# M2Sxxx register map
Vendor: Microsemi; Series: SmartFusion2; File version: 2.0.32
CPU: CM3 r2p1, little endian, MPU, no FPU, 4 interrupt priority bits
Registers are 32-bit, read-write, no defined reset value unless marked. A register's access mark holds for its fields unless they carry their own. Offsets are from the block's base; [hi:lo] are bit positions; {n}, {i} and the like mark numbered series.

## MMUART_0 — Multi-mode universal asynchronous/synchronous receiver/transmitter peripheral
Base 0x40000000
Same registers: MMUART_1 0x40010000
0x00 RBR 8-bit — Receiver buffer register. This register holds the receive data bits for MMUART_x. The default value is unknown since the register is loaded with data in the receive FIFO. Bit 0 is the LSB and it is the first bit received. It may be configured as the MSB by configuring the E_MSB_RX bit in the MM1. The divisor latch access bit (DLAB), bit 7 of LCR, must be 0 to read this register. This register is read only. Writing to this register with the DLAB 0 changes the transmit holding register (THR) register value.
0x00 THR 8-bit (alternate view of RBR) — Transmit holding register. This register holds the data bits to be transmitted. Bit 0 is the LSB and is transmitted first. The MSB may be transmitted first, if it is configured with the E_MSB_TX bit in the MM1. The reset value is unknown since the register is loaded with data in the transmit FIFO. The DLAB, bit 7 of LCR, must be 0 to write to this register. This register is write only. Reading from this register with the DLAB 0 reads the RBR register value.
0x00 DLR 8-bit (alternate view of RBR) — Divisor latch (LSB)
  [7:0] DLR — This divisor latch LSB register (DLR) holds the LSB of the integer divisor value used to calculate the baud rate. The baud rate can be calculated using EQ 1, 2, 3, or 4.
0x04 DMR 8-bit — Divisor latch (MSB)
  [7:0] DMR — This divisor latch MSB register (DMR) holds the MSB of the integer divisor value used to calculate the baud rate. The baud rate can be calculated using EQ 1, 2, 3, or 4.
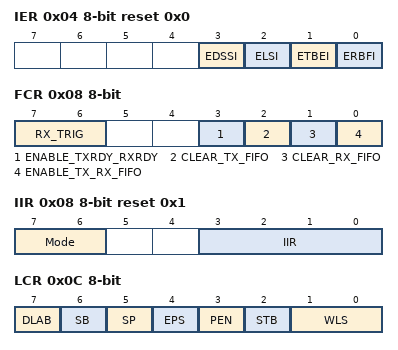
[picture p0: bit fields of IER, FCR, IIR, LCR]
0x04 IER 8-bit reset 0x0 — Interupt Enable Register
  [3] EDSSI — Modem status interrupt enable
  [2] ELSI — Receiver line status interrupt enable
  [1] ETBEI — Transmitter holding register empty interrupt enable
  [0] ERBFI — Enables received data available interrupt
0x08 FCR 8-bit — FIFO control register
  [7:6] RX_TRIG wo — These bits are used to set the trigger level for the Rx FIFO interrupt. Rx FIFO trigger level (bytes) are: 0b00: 1 byte 0b01: 4 bytes 0b10: 8 bytes 0b11: 14 bytes
    0=FIFO_1_Byte; 1=FIFO_4_Bytes; 2=FIFO_8_Bytes; 3=FIFO_14_Bytes
  [3] ENABLE_TXRDY_RXRDY wo — Software must always set this bit to 1 for efficient data transfer from transmit FIFO to PDMA.
  [2] CLEAR_TX_FIFO wo — Clears all bytes in the Tx FIFO and resets its counter logic. The shift register is not cleared. 0: Disabled (default) 1: Enabled
  [1] CLEAR_RX_FIFO wo — Clears all bytes in Rx FIFO and resets counter logic. This shift register is not cleared. 0: Disabled (default) 1: Enabled
  [0] ENABLE_TX_RX_FIFO wo — It enables both the Tx and Rx FIFOs and is hardwired to 1, which means it is always enabled and cannot be changed.
0x08 IIR 8-bit ro reset 0x1 — Interrupt identification register
  [7:6] Mode — Always 0b11. Enables FIFO mode.
  [3:0] IIR — Interrupt identification bits.
    6=Receiver_Line_Status (Highest priority. Receiver line status interrupts due to overrun error, parity error, framing error, or break interrupt. Reading the line status register resets this interrupt.); 4=Receiver_Data_Available (Second priority. Receive data available interrupt modem status interrupt. Reading the receiver buffer register (RBR) or the FIFO drops below the trigger level resets this interrupt.); 12=Character_Timeout_Indication (Second priority. Character timeout indication interrupt occurs when no characters have been read from the Rx FIFO during the last four character times and there was at least one character in it during this time. Reading the RBR resets this interrupt.); 2=Transmitter_Holding_Register_Empty (Third priority. Transmit holding register empty interrupt. Reading the IIR or writing to the transmit holding register (THR) resets the interrupt.); 0=Modem_Status (Fourth priority. Modem status interrupt due to clear to send, data set ready, ring indicator, or data carrier detect being asserted. Reading the modem status register resets this interrupt.); 3=Multi_Mode_Interrupt (Fifth priority. Multi-mode interrupts can occur due to any of the interrupts mentioned in IIM. For more details refer to Table 12-15.)
0x0C LCR 8-bit — Line Control register
  [7] DLAB — Divisor latch access bit. Enables access to the divisor latch registers during read or write operation to address 0 and 1.
  [6] SB — Set break. Enabling this bit sets MMUART_x_TXD to 0. This does not have any effect on transmitter logic.
  [5] SP — Stick parity. When stick parity is enabled, the parity is set according to bits [4:3] as follows: 11: 0 will be sent as a parity bit and checked when receiving. 01: 1 will be sent as a parity bit and checked when receiving.
  [4] EPS — Even parity select
    0=Odd (Odd parity); 1=Even parity
  [3] PEN — Parity enable
  [2] STB — Number of stop bits (STB)
    0=Stop_Bit_1 (1 stop bit); 1=Stop_Bit_1_and_half (1 1/2 stop bits when WLS=00. The number of stop bits is 2 for all other cases not described above (STB=1 and WLS=01, 10, or 11).)
  [1:0] WLS — Word length select
    {v}=Length_{v+5}_Bits (v=0..3)
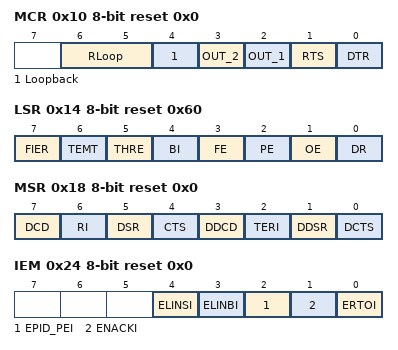
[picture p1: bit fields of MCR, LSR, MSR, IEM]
0x10 MCR 8-bit reset 0x0 — Modem Control register
  [6:5] RLoop — Remote loopback enable bits. In the Remote loopback mode, when a bit is received, it is sent directly out the transmit line, bypassing the transmitter block, and disabling the receiver. In the Automatic echo mode, when a bit is received, it is sent directly out the transmit line, bypassing the transmitter block, while the receiver is still enabled.
    0=Disabled; 1=Enabled (Remote loopback enabled); 2=Echo (Automatic echo enabled)
  [4] Loopback — In the Loopback mode, MMUART_x_TXD is set to 1. The MMUART_x_RXD, MMUART_x_DSR, MMUART_x_CTS, MMUART_x_RI, and MMUART_x_DCD inputs are disconnected. The output of the transmitter shift register is looped back into the receiver shift register. The modem control outputs (MMUART_x_DTR, MMUART_x_RTS, MMUART_x_OUT1, and MMUART_x_OUT2) are connected internally to the modem control inputs, and the modem control output pins are set as 1. The transmitted data is immediately received, allowing Cortex-M3 processor to check the operation of the MMUART_x. The interrupts are operating in the Loopback mode.
  [3] OUT_2 — Controls the output2 (OUT2) signal. Active Low
    0=Set_1; 1=Set_0
  [2] OUT_1 — Controls the output1 (OUT1) signal. Active Low
    0=Set_1; 1=Set_0
  [1] RTS — Controls the request to send (MMUART_x_RTS) signal. Active Low
    0=Set_1; 1=Set_0
  [0] DTR — Data terminal ready (MMUART_x_DTR) output. Active Low
    0=Set_1; 1=Set_0
0x14 LSR 8-bit ro reset 0x60 — Line Status register
  [7] FIER — This bit is set when there is at least one parity error, framing error, or break indication in the FIFO. FIER is cleared when Cortex-M3 processor reads the LSR, if there are no subsequent errors in the FIFO.
  [6] TEMT — Transmit empty (TEMT). This bit is set to 1 when both the transmitter FIFO and shift registers are empty.
  [5] THRE — Transmitter holding register empty (THRE). Indicates that the MMUART_x is ready to transmit a new data byte. THRE causes an interrupt to the Cortex-M3 processor when bit 1 (ETBEI) in the interrupt enable register is 1. This bit is set when the Tx FIFO is empty. It is cleared when at least one byte is written to the Tx FIFO.
  [4] BI — Break interrupt (BI). Indicates that the receive data is at 0 longer than a full word transmission time (start bit + data bits + parity + stop bits). BI is cleared when Cortex-M3 processor reads the line status register (LSR). This error is revealed to the Cortex-M3 processor when it is associated character is at the top of the FIFO. When break occurs, only one zero character is loaded into the FIFO.
  [3] FE — Framing error (FE). Indicates that the receive byte did not have a valid stop bit. FE is cleared when Cortex-M3 processor reads the LSR. The MMUART_x tries to resynchronize after a framing error. To do this, it assumes that the framing error was due to the next start bit, so it samples this start bit twice, and then starts receiving the data. This error is revealed to Cortex-M3 processor when it is associated character is at the top of the FIFO.
  [2] PE — Parity error (PE). Indicates that the receive byte had a parity error. PE is cleared when the Cortex-M3 processor reads the LSR. This error is revealed to the Cortex-M3 processor when it is associated character is at the top of the FIFO.
  [1] OE — Overrun error (OE). Indicates that the new byte was received before the Cortex-M3 processor reads the byte from the receive buffer, and that the earlier data byte was destroyed. OE is cleared when the Cortex-M3 processor reads the LSR. If the data continues to fill the FIFO beyond the trigger level, an overrun error occurs once the FIFO is full and the next character has been completely received in the shift register. The character in the shift register is overwritten, but it is not transferred to the FIFO.
  [0] DR — Data ready (DR). Indicates when a data byte is received and stored in the receive buffer or the FIFO. DR is cleared to 0 when the Cortex-M3 processor reads the data from the receive buffer or the FIFO.
0x18 MSR 8-bit ro reset 0x0 — Modem Status register
  [7] DCD — Data carrier detect (DCD) (MMUART_x_DCD).The complement of DCD input. When bit 4 of the MCR is set to 1 (loop), this bit is equivalent to OUT2 in the MCR.
  [6] RI — Ring indicator (RI) (MMUART_x_RI). The complement of the RI input. When bit 4 of the MCR is set to 1 (loop), this bit is equivalent to OUT1 in the MCR.
  [5] DSR — Data set ready (DSR) (MMUART_x_DSR). The complement of the DSR input. When bit 4 of the MCR is set to 1 (loop), this bit is equivalent to RTS in the MCR.
  [4] CTS — Clear to send (CTS) (MMUART_x_CTS). The complement of the CTS input. When bit 4 of the MCR is set to 1 (loop), this bit is equivalent to DTR in the MCR.
  [3] DDCD — Delta data carrier detect (DDCD) indicator. Indicates that DCD input has changed state. Whenever bit 0, 1, 2, or 3 is set to 1, a modem status interrupt is generated.
  [2] TERI — Trailing edge of ring indicator (TERI) detector. Indicates that RI input has changed from 0 to 1. Whenever bit 0, 1, 2, or 3 is set to 1, a modem status interrupt is generated.
  [1] DDSR — Delta data set ready (DDSR) indicator. Indicates that the DSRn input has changed state since the last time it was read by the Cortex-M3 processor. Whenever bit 0, 1, 2, or 3 is set to 1, a modem status interrupt is generated.
  [0] DCTS — Delta clear to send (DCTS) indicator. Indicates that the CTSn input has changed state since the last time it was read by the Cortex-M3 processor. Whenever bit 0, 1, 2, or 3 is set to 1, a modem status interrupt is generated.
0x1C SR 8-bit reset 0x0 — Scratch register. This register has no effect on MMUART_x operation.
0x24 IEM 8-bit reset 0x0 — Multi-mode interrupt enable register
  [4] ELINSI — Enables the LIN sync detection interrupt
  [3] ELINBI — Enables LIN break interrupt
  [2] EPID_PEI — Enables PID parity error interrupt
  [1] ENACKI — Enables NACK interrupt
  [0] ERTOI — Enables receiver timeout interrupt
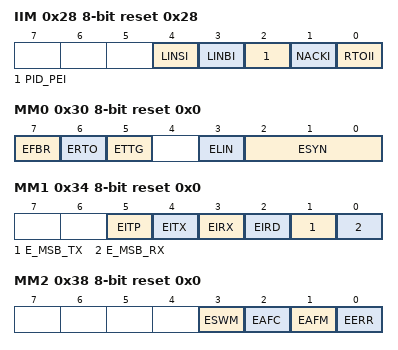
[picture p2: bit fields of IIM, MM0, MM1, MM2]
0x28 IIM 8-bit reset 0x28 — Multi-mode Interrupt identification register
  [4] LINSI — LIN sync detection interrupt ID. This bit set when 5th falling edge is detected by the sync timer. It resets the FIFO address pointers so that the PID will be in the first location. Reading the IIM register clears this interrupt.
  [3] LINBI — LIN break interrupt, set automatically when break length of 11.5 Tbits is detected. Reading the IIM register clears this interrupt.
  [2] PID_PEI — Protected identifier field (PID) parity error interrupt is generated when there is a mismatch in PID in LIN header, that is, when either the P0 or P1 bits in the incoming PID byte do not match the calculated P0 and P1 error.
  [1] NACKI — NACK interrupt is asserted when EERR bit is set in MM2. Reading the MM2 clears the interrupt.
  [0] RTOII — Receiver time-out (RTO) interrupt ID. RTO interrupt is asserted when RTO value is reached by the counter. It gets cleared when writing to the RTO register.
0x30 MM0 8-bit reset 0x0 — Multi-mode control register 0
  [7] EFBR — Enable fractional baud rate (FBR) mode.
  [6] ERTO — Enable receiver timeout (RTO). Writing this bit enables the timeout and restarts the counter value. The timeout value is determined by the RTO register.
  [5] ETTG — Enable transmitter time guard (TTG). The time guard value is determined by the TTG Register.
  [3] ELIN — Enable LIN header detection and automatic baud rate calculation.
  [2:0] ESYN — Enable synchronous operation. There are four types of Synchronous Operation modes that can be enabled.
    0=Disabled, that is, Asynchronous mode; 1=Slave_Positive_Edge (Synchronous slave enabled, positive-edge clock); 2=Slave_Negative_Edge (Synchronous slave enabled, negative-edge clock); 3=Master_Positive_Edge (Synchronous master enabled, positive-edge clock); 4=Master_Negative_Edge (Synchronous master enabled, negative-edge clock)
0x34 MM1 8-bit reset 0x0 — Multi-mode control register 1
  [5] EITP — Output pulse width for RZI mod can be modified using this bit.
    0=Width_3_16 (3/16th Tbit pulse width); 1=Width_1_4 (1/4th Tbit pulse width.)
  [4] EITX — You can configure output polarity for RZI modulation.
    0=Active_Low (RZI output pulses are active Low, signifying a low NRZ value); 1=Active_High (RZI output pulses are active High, signifying a high NRZ value)
  [3] EIRX — You can configure input polarity for RZI demodulation.
    0=Active_Low (RZI input pulses are active Low, signifying a low NRZ value); 1=Active_High (RZI input pulses are active High, signifying a high NRZ value)
  [2] EIRD — Enables RZI modulation/demodulation.
  [1] E_MSB_TX — LSB or MSB can be sent first by configuring this bit. By default, the "THR" bit 0 is the LSB, and is the first transmitted bit. Bit 0 of the THR may be configured as the last transmitted bit, MSB.
  [0] E_MSB_RX — LSB or MSB can be received first by configuring this bit. By default, the receiver buffer register's (RBR) bit 0 is the LSB, and is the first received bit. Bit 0 of the RBR may be configured as the last received bit, MSB.
0x38 MM2 8-bit reset 0x0 — Multi-mode control register 2
  [3] ESWM — Enable single-wire, half-duplex mode.
  [2] EAFC — Enable a flag clear (EAFC). When EAFM is enabled the Rx FIFO is disabled until another address flag with matching address is received. The bit gets cleared on write in multi-mode control registers 2.
  [1] EAFM — Enable automatic 9-bit address flag mode (EAFM). It should be noted that for enabling this bit it requires, the LCR should be in an 8-bit and stick parity (SP) bit configured to 0. If EAFM bit is disabled, the Rx FIFO is enabled by receiving all the bytes. When EAFM bit is enabled, the Rx FIFO is disabled until an address flag with matching address is received.
  [0] EERR — When the EERR bit is set, the receiver forces an error signal transmit out, if an incoming parity error is detected. Error signal (ACK/NACK) is sent during stop time enable.
0x3C DFR 8-bit — Divisor Fractional Register
  [5:0] DFR — The fractional divisor register (DFR) is used to store the fractional divisor used to calculate the fractional baud rate value in 1/64th using EQ 5. 0x0: 0/64 0x1: 1/64 etc.
0x44 GFR 8-bit reset 0x0 — Glitch filter register
  [2:0] GLR
    0=Two_Flip_Flops_No_Spike (Two resynchronize flip-flops are used but there is no spike suppression.); 1=Three_Flip_Flops_No_Spike (Three resynchronize flip-flops are used but there is no spike suppression.); {v}=Three_Flip_Flops_{v-1}_Cycle_Suppression (Three resynchronize flip-flops are used and it also causes {v-1} APB clock cycle suppression.) (v=2..7)
0x48 TTG 8-bit reset 0x0 — Transmitter time guard register. If the transmitter time guard is enabled from the multi-mode control register 0 (MM0), the transmitter time guard value determines the amount of system clock cycles to wait between transmissions. The time guard equation is based on the baud rate bit time (Tbit) value as follows: Tx Time Guard Value = TTG x Bit Time (Tbit)
0x4C RTO 8-bit reset 0x0 — Receiver time-tou receiver. Writing to the RTO register sets the counter value and enables, if the ERTO bit in the MM0 is enabled. You can configure the timeout value by writing into this register. The RTO counts when the Rx block input state is idle; is reset when a start condition occurs, and restarts counting upon returning to the idle state. When the RTO value is reached, the RTOII interrupt is set. Re-writing the RTO register clears the interrupt and sets the counter. The receiver timeout value equation is based on the baud rate bit time (Tbit) as follows: Rx Timeout Value = 4 x RTO x Bit Time (Tbit)
0x50 ADR 8-bit reset 0x0 — Address register. The address register is used in 9-bit Address Flag mode. When an address flag is received on the 9th bit, and EAFM is set in MM2, the incoming data is checked against the address register. If a match occurs, the Rx FIFO is enabled.
